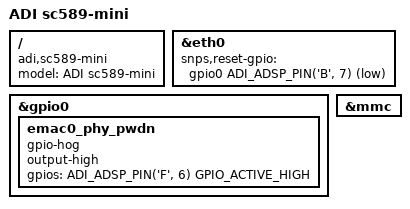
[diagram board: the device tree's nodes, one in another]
// SPDX-License-Identifier: GPL-2.0-or-later
/*
 * (C) Copyright 2022 - Analog Devices, Inc.
 *
 * Written and/or maintained by Timesys Corporation
 *
 * Contact: Nathan Barrett-Morrison <nathan.morrison@timesys.com>
 * Contact: Greg Malysa <greg.malysa@timesys.com>
 */

/dts-v1/;

#include "sc5xx.dtsi"
#include "sc58x.dtsi"

/ {
	model = "ADI sc589-mini";
	compatible = "adi,sc589-mini", "adi,sc58x";
};

&eth0 {
	snps,reset-gpio = <&gpio0 ADI_ADSP_PIN('B', 7) GPIO_ACTIVE_LOW>;
};

&gpio0 {
	emac0_phy_pwdn {
		gpio-hog;
		output-high;
		gpios = <ADI_ADSP_PIN('F', 6) GPIO_ACTIVE_HIGH>;
	};
};

&mmc {
	status = "okay";
};
